AUTOSAR XML (schema 4-1-1)
standard types defined: uint8_DataConstr, Boolean, uint16
package /ComponentTypes
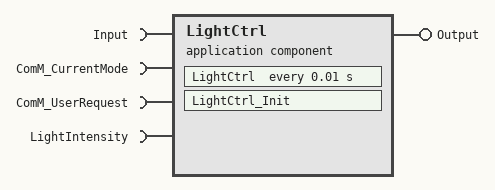
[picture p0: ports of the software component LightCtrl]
  application sw component type LightCtrl
    require port Input: nonqueued-receiver-com-spec{data-element=LightSwitch, alive-timeout=60, init-value=constant-reference={short-label=DefaultInitValue_uint8, constant=DefaultInitValue_uint8}}, required-interface=Input
    provide port Output: nonqueued-sender-com-spec{data-element=HeadLight, init-value=constant-reference={short-label=DefaultInitValue_Boolean, constant=DefaultInitValue_Boolean}}, provided-interface=Output
    require port ComM_CurrentMode: required-interface=ComM_CurrentMode
    require port ComM_UserRequest: required-interface=ComM_UserRequest
    require port LightIntensity: required-interface=LightIntensity
    behavior LightCtrl_InternalBehavior: handle-termination-and-restart=NO-SUPPORT
      timing event TMT_LightCtrl: start-on-event=LightCtrl, period=0.01
      runnable LightCtrl
        data-receive-point-by-arguments:
          access IN_Input_LightSwitch: accessed-variable=Input.LightSwitch
        data-send-points:
          access OUT_Output_HeadLight: accessed-variable=Output.HeadLight
        sync call SC_LightIntensity_LightIntensity: operation=LightIntensity.LightIntensity, timeout=1.0e-06
      runnable LightCtrl_Init
        data-send-points:
          access OUT_Output_HeadLight: accessed-variable=Output.HeadLight
package /MICROSAR_SWCS_DEV/ComM_swc
  mode declaration group ComMMode: category=ALPHABETICAL, initial-mode=COMM_NO_COMMUNICATION
    mode COMM_FULL_COMMUNICATION
    mode COMM_NO_COMMUNICATION
    mode COMM_SILENT_COMMUNICATION
package /MICROSAR_SWCS_DEV/ComM_swc/DataTypes
  impl type ComM_ModeType: category=VALUE, base-type=sint32, compu {0=COMM_NO_COMMUNICATION, 1=COMM_SILENT_COMMUNICATION, 2=COMM_FULL_COMMUNICATION}
package /MICROSAR_SWCS_DEV/ComM_swc/DataTypes/CompuMethods
  compu method COMPU_Boolean: 0=FALSE, 1=TRUE
  unit NoUnit: factor-si-to-unit=1, offset-si-to-unit=0
package /MICROSAR_SWCS_DEV/IoHwAb_swc/DataTypes/DataConstrs
  range uint16_Constr: raw 0..65535
